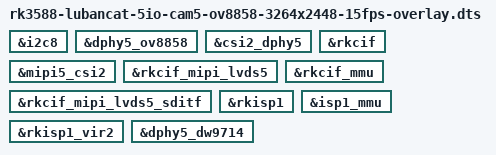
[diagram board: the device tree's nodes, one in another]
/dts-v1/;
/plugin/;

#include <dt-bindings/usb/pd.h>
#include <dt-bindings/gpio/gpio.h>
#include <dt-bindings/pwm/pwm.h>
#include <dt-bindings/pinctrl/rockchip.h>
#include <dt-bindings/input/rk-input.h>
#include <dt-bindings/display/drm_mipi_dsi.h>
#include <dt-bindings/display/rockchip_vop.h>
#include <dt-bindings/sensor-dev.h>

/ {
/* Link path: sensor->csi2_dphy1->mipi2_csi2->rkcif_mipi_lvds2--->rkcif_mipi_lvds2_sditf->rkisp0_vir2 */
	fragment@0 {
		target = <&i2c8>;
		__overlay__ {
			status = "okay";
		};
	};

	fragment@1 {
		target = <&dphy5_ov8858>;
		__overlay__ {
			status = "okay";
		};
	};

	fragment@3 {
		target = <&csi2_dphy5>;

		__overlay__ {
			status = "okay";
		};
	};

	fragment@4 {
		target = <&mipi5_csi2>;

		__overlay__ {
			status = "okay";
		};
	};

	fragment@5 {
		target = <&rkcif>;

		__overlay__ {
			status = "okay";
		};
	};

	fragment@6 {
		target = <&rkcif_mipi_lvds5>;

		__overlay__ {
			status = "okay";
		};
	};

	fragment@7 {
		target = <&rkcif_mipi_lvds5_sditf>;

		__overlay__ {
			status = "okay";
		};
	};

	fragment@8 {
		target = <&rkcif_mmu>;

		__overlay__ {
			status = "okay";
		};
	};

	fragment@9 {
		target = <&rkisp1>;

		__overlay__ {
			status = "okay";
		};
	};

	fragment@10 {
		target = <&isp1_mmu>;

		__overlay__ {
			status = "okay";
		};
	};

	fragment@11 {
		target = <&rkisp1_vir2>;

		__overlay__ {
			status = "okay";
		};
	};

	fragment@12 {
		target = <&dphy5_dw9714>;

		__overlay__ {
			status = "okay";
		};
	};
};

